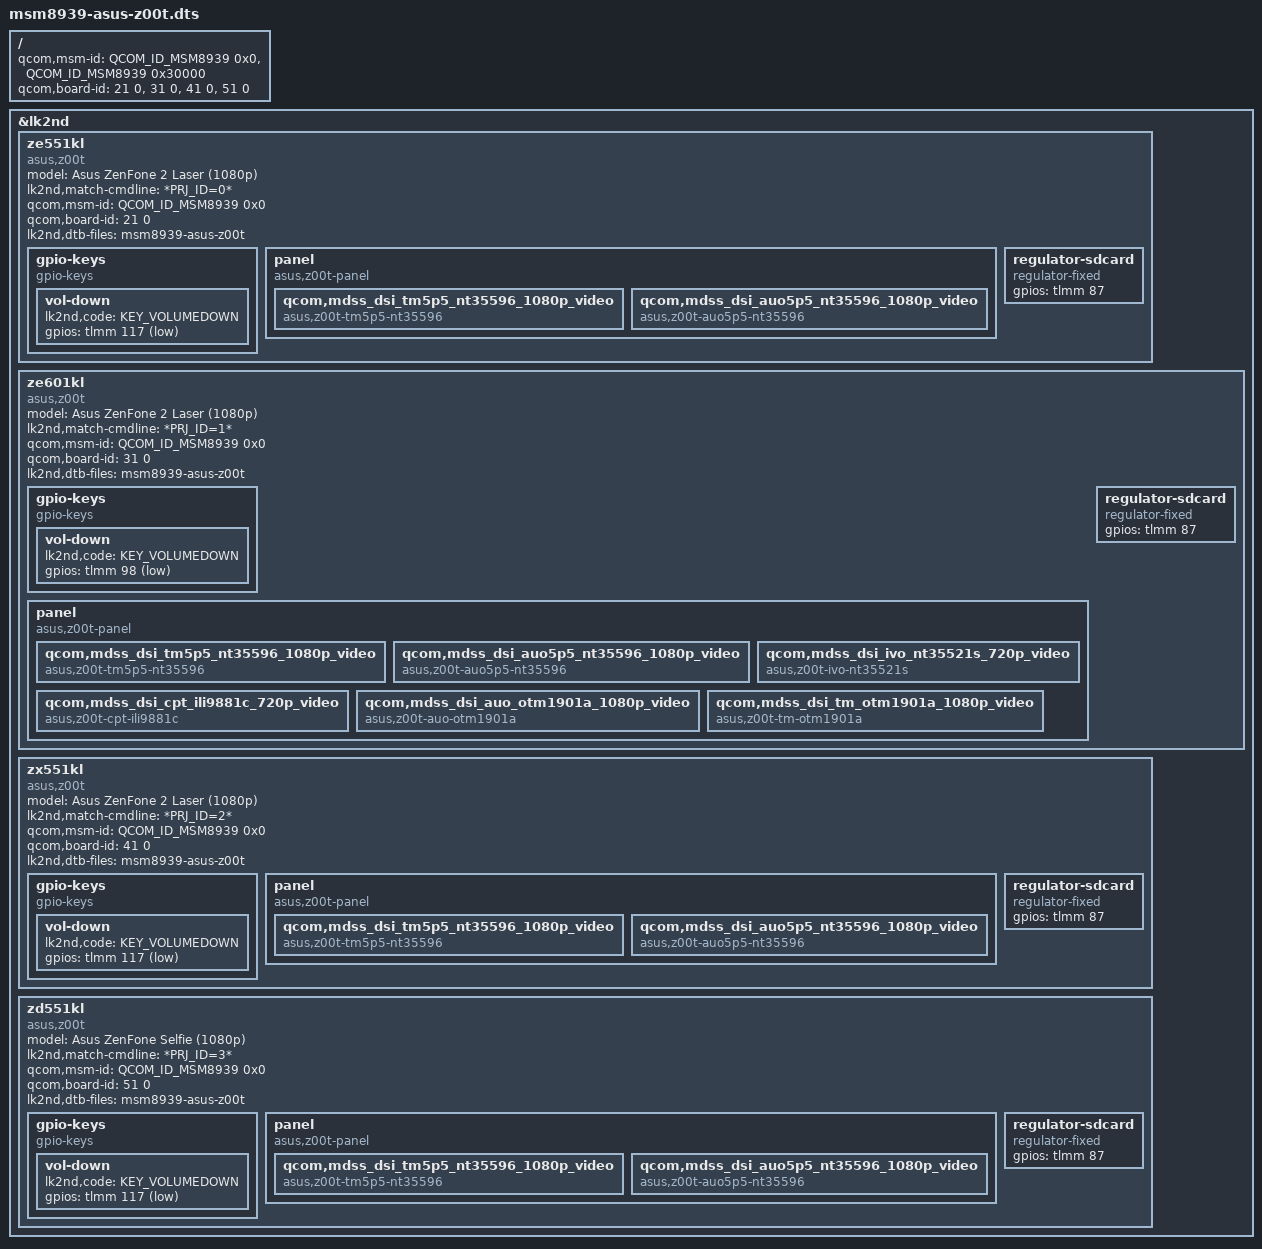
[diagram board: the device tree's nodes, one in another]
// SPDX-License-Identifier: BSD-3-Clause

#include <skeleton64.dtsi>
#include <lk2nd.dtsi>

/ {
	qcom,msm-id = <QCOM_ID_MSM8939 0x0>, <QCOM_ID_MSM8939 0x30000>;
	qcom,board-id = <21 0>, <31 0>, <41 0>, <51 0>;
};

&lk2nd {
	ze551kl {
		model = "Asus ZenFone 2 Laser (1080p)";
		compatible = "asus,z00t";
		lk2nd,match-cmdline = "*PRJ_ID=0*";

		qcom,msm-id = <QCOM_ID_MSM8939 0x0>;
		qcom,board-id = <21 0>;

		lk2nd,dtb-files = "msm8939-asus-z00t";

		gpio-keys {
			compatible = "gpio-keys";

			vol-down {
				lk2nd,code = <KEY_VOLUMEDOWN>;
				gpios = <&tlmm 117 (GPIO_ACTIVE_LOW | GPIO_PULL_UP)>;
			};
		};

		panel {
			compatible = "asus,z00t-panel", "lk2nd,panel";

			qcom,mdss_dsi_tm5p5_nt35596_1080p_video {
				compatible = "asus,z00t-tm5p5-nt35596";
			};
			qcom,mdss_dsi_auo5p5_nt35596_1080p_video {
				compatible = "asus,z00t-auo5p5-nt35596";
			};
		};

		regulator-sdcard {
			compatible = "regulator-fixed";
			gpios = <&tlmm 87 GPIO_ACTIVE_HIGH>;
		};
	};
	
	ze601kl {
		model = "Asus ZenFone 2 Laser (1080p)";
		compatible = "asus,z00t";
		lk2nd,match-cmdline = "*PRJ_ID=1*";

		qcom,msm-id = <QCOM_ID_MSM8939 0x0>;
		qcom,board-id = <31 0>;

		lk2nd,dtb-files = "msm8939-asus-z00t";

		gpio-keys {
			compatible = "gpio-keys";

			vol-down {
				lk2nd,code = <KEY_VOLUMEDOWN>;
				gpios = <&tlmm 98 (GPIO_ACTIVE_LOW | GPIO_PULL_UP)>;
			};
		};

		panel {
			compatible = "asus,z00t-panel", "lk2nd,panel";

			qcom,mdss_dsi_tm5p5_nt35596_1080p_video {
				compatible = "asus,z00t-tm5p5-nt35596";
			};
			qcom,mdss_dsi_auo5p5_nt35596_1080p_video {
				compatible = "asus,z00t-auo5p5-nt35596";
			};

			qcom,mdss_dsi_ivo_nt35521s_720p_video {
				compatible = "asus,z00t-ivo-nt35521s";
			};

			qcom,mdss_dsi_cpt_ili9881c_720p_video {
				compatible = "asus,z00t-cpt-ili9881c";
			};

			qcom,mdss_dsi_auo_otm1901a_1080p_video {
				compatible = "asus,z00t-auo-otm1901a";
			};

			qcom,mdss_dsi_tm_otm1901a_1080p_video {
				compatible = "asus,z00t-tm-otm1901a";
			};
		};

		regulator-sdcard {
			compatible = "regulator-fixed";
			gpios = <&tlmm 87 GPIO_ACTIVE_HIGH>;
		};
	};

	zx551kl {
		model = "Asus ZenFone 2 Laser (1080p)";
		compatible = "asus,z00t";
		lk2nd,match-cmdline = "*PRJ_ID=2*";

		qcom,msm-id = <QCOM_ID_MSM8939 0x0>;
		qcom,board-id = <41 0>;

		lk2nd,dtb-files = "msm8939-asus-z00t";

		gpio-keys {
			compatible = "gpio-keys";

			vol-down {
				lk2nd,code = <KEY_VOLUMEDOWN>;
				gpios = <&tlmm 117 (GPIO_ACTIVE_LOW | GPIO_PULL_UP)>;
			};
		};

		panel {
			compatible = "asus,z00t-panel", "lk2nd,panel";

			qcom,mdss_dsi_tm5p5_nt35596_1080p_video {
				compatible = "asus,z00t-tm5p5-nt35596";
			};
			qcom,mdss_dsi_auo5p5_nt35596_1080p_video {
				compatible = "asus,z00t-auo5p5-nt35596";
			};
		};

		regulator-sdcard {
			compatible = "regulator-fixed";
			gpios = <&tlmm 87 GPIO_ACTIVE_HIGH>;
		};
	};

	zd551kl {
		model = "Asus ZenFone Selfie (1080p)";
		compatible = "asus,z00t";
		lk2nd,match-cmdline = "*PRJ_ID=3*";

		qcom,msm-id = <QCOM_ID_MSM8939 0x0>;
		qcom,board-id = <51 0>;

		lk2nd,dtb-files = "msm8939-asus-z00t";

		gpio-keys {
			compatible = "gpio-keys";

			vol-down {
				lk2nd,code = <KEY_VOLUMEDOWN>;
				gpios = <&tlmm 117 (GPIO_ACTIVE_LOW | GPIO_PULL_UP)>;
			};
		};

		panel {
			compatible = "asus,z00t-panel", "lk2nd,panel";

			qcom,mdss_dsi_tm5p5_nt35596_1080p_video {
				compatible = "asus,z00t-tm5p5-nt35596";
			};
			qcom,mdss_dsi_auo5p5_nt35596_1080p_video {
				compatible = "asus,z00t-auo5p5-nt35596";
			};
		};

		regulator-sdcard {
			compatible = "regulator-fixed";
			gpios = <&tlmm 87 GPIO_ACTIVE_HIGH>;
		};
	};
};
